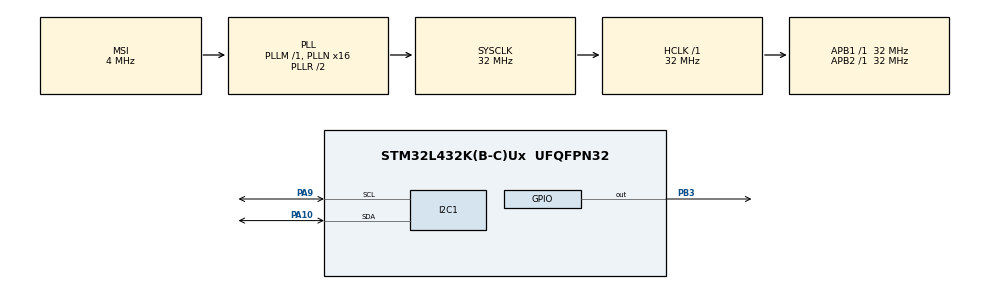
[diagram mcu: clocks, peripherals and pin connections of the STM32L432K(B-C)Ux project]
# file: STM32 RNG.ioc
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I2C1.OwnAddress=42
I2C1.Timing=0x00B07CB4
Mcu.Family=STM32L4
Mcu.Name=STM32L432K(B-C)Ux
Mcu.Package=UFQFPN32
NUCLEO-L432KC.LD3=true
NVIC.I2C1_ER_IRQn=true\:0\:0\:false\:false\:true\:true\:true\:true
NVIC.I2C1_EV_IRQn=true\:0\:0\:false\:false\:true\:true\:true\:true
NVIC.PriorityGroup=NVIC_PRIORITYGROUP_4
PA0.GPIO_Label=MCO [High speed clock in]
PA0.Signal=RCC_CK_IN
PA10.GPIO_Pu=GPIO_PULLUP
PA10.Mode=I2C
PA10.Signal=I2C1_SDA
PA13\ (JTMS-SWDIO).GPIO_Label=SWDIO
PA13\ (JTMS-SWDIO).Signal=SYS_JTMS-SWDIO
PA14\ (JTCK-SWCLK).GPIO_Label=SWCLK
PA14\ (JTCK-SWCLK).Signal=SYS_JTCK-SWCLK
PA15\ (JTDI).GPIO_Label=VCP_RX
PA15\ (JTDI).Signal=USART2_RX
PA2.GPIO_Label=VCP_TX
PA2.Signal=USART2_TX
PA9.GPIO_Pu=GPIO_PULLUP
PA9.Mode=I2C
PA9.Signal=I2C1_SCL
PB3\ (JTDO-TRACESWO).Signal=GPIO_Output
PC14-OSC32_IN\ (PC14).Signal=RCC_OSC32_IN
PC15-OSC32_OUT\ (PC15).Signal=RCC_OSC32_OUT
ProjectManager.HeapSize=0x200
ProjectManager.StackSize=0x400
ProjectManager.TargetToolchain=STM32CubeIDE
RCC.AHBFreq_Value=32000000
RCC.APB1Freq_Value=32000000
RCC.APB1TimFreq_Value=32000000
RCC.APB2Freq_Value=32000000
RCC.APB2TimFreq_Value=32000000
RCC.CortexFreq_Value=32000000
RCC.HCLKFreq_Value=32000000
RCC.HSE_VALUE=8000000
RCC.HSI16_VALUE=16000000
RCC.HSI48_VALUE=48000000
RCC.HSI_VALUE=16000000
RCC.LSE_VALUE=32768
RCC.MSI_VALUE=4000000
RCC.PLLMUL=RCC_PLLMUL_4
RCC.PLLN=16
RCC.SYSCLKFreq_VALUE=32000000
RCC.SYSCLKSource=RCC_SYSCLKSOURCE_PLLCLK
RCC.VCOOutputFreq_Value=64000000
VP_NUCLEO-L432KC_VS_BSP_COMMON.Mode=COMMON
board=NUCLEO-L432KC

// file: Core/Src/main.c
/* USER CODE BEGIN Header */
/**
  ******************************************************************************
  * @file           : main.c
  * @brief          : Main program body
  ******************************************************************************
  * @attention
  *
  * Copyright (c) 2026 STMicroelectronics.
  * All rights reserved.
  *
  * This software is licensed under terms that can be found in the LICENSE file
  * in the root directory of this software component.
  * If no LICENSE file comes with this software, it is provided AS-IS.
  *
  ******************************************************************************
  */
/* USER CODE END Header */
#include "main.h"

/* USER CODE BEGIN Includes */
#include <stdio.h>
#include <stdlib.h>
#include <time.h>
/* USER CODE END Includes */

I2C_HandleTypeDef hi2c1;

/* USER CODE BEGIN PV */
volatile uint8_t restart = 1;
/* USER CODE END PV */

void SystemClock_Config(void);
static void MX_GPIO_Init(void);
static void MX_I2C1_Init(void);
/* USER CODE BEGIN PFP */
void HAL_I2C_SlaveTxCpltCallback(I2C_HandleTypeDef *hi2c)
{
	restart = 1;

}
/* USER CODE END PFP */

int main(void)
{

  /* MCU Configuration--------------------------------------------------------*/

  /* Reset of all peripherals, Initializes the Flash interface and the Systick. */
  HAL_Init();

  /* Configure the system clock */
  SystemClock_Config();

  /* Initialize all configured peripherals */
  MX_GPIO_Init();
  MX_I2C1_Init();

  /* Initialize leds */
  BSP_LED_Init(LED_GREEN);

  /* Infinite loop */
  /* USER CODE BEGIN WHILE */

  uint8_t payload[3], test = {0};
  srand((unsigned int)time(NULL));
  while (1)
  {
	  payload[0] = (rand() % 5) + 1;
	  payload[1] = (rand() % 5) + 1;
	  payload[2] = (rand() % 10) + 1;
    /* USER CODE END WHILE */

    /* USER CODE BEGIN 3 */
	  if (restart)
	          {
	              restart = 0;

	              // regenerate all RNG numbers
	              payload[0] = (uint8_t)((rand() % 5) + 1);
	              payload[1] = (uint8_t)((rand() % 5) + 1);
	              payload[2] = (uint8_t)((rand() % 10) + 1);

	              // re-arm the listener
	              HAL_I2C_Slave_Transmit_IT(&hi2c1, payload, 3);
	          }
  }
  /* USER CODE END 3 */
}

void SystemClock_Config(void)
{
  RCC_OscInitTypeDef RCC_OscInitStruct = {0};
  RCC_ClkInitTypeDef RCC_ClkInitStruct = {0};

  /** Configure the main internal regulator output voltage
  */
  if (HAL_PWREx_ControlVoltageScaling(PWR_REGULATOR_VOLTAGE_SCALE1) != HAL_OK)
  {
    Error_Handler();
  }

  /** Initializes the RCC Oscillators according to the specified parameters
  * in the RCC_OscInitTypeDef structure.
  */
  RCC_OscInitStruct.OscillatorType = RCC_OSCILLATORTYPE_MSI;
  RCC_OscInitStruct.MSIState = RCC_MSI_ON;
  RCC_OscInitStruct.MSICalibrationValue = 0;
  RCC_OscInitStruct.MSIClockRange = RCC_MSIRANGE_6;
  RCC_OscInitStruct.PLL.PLLState = RCC_PLL_ON;
  RCC_OscInitStruct.PLL.PLLSource = RCC_PLLSOURCE_MSI;
  RCC_OscInitStruct.PLL.PLLM = 1;
  RCC_OscInitStruct.PLL.PLLN = 16;
  RCC_OscInitStruct.PLL.PLLP = RCC_PLLP_DIV7;
  RCC_OscInitStruct.PLL.PLLQ = RCC_PLLQ_DIV2;
  RCC_OscInitStruct.PLL.PLLR = RCC_PLLR_DIV2;
  if (HAL_RCC_OscConfig(&RCC_OscInitStruct) != HAL_OK)
  {
    Error_Handler();
  }

  /** Initializes the CPU, AHB and APB buses clocks
  */
  RCC_ClkInitStruct.ClockType = RCC_CLOCKTYPE_HCLK|RCC_CLOCKTYPE_SYSCLK
                              |RCC_CLOCKTYPE_PCLK1|RCC_CLOCKTYPE_PCLK2;
  RCC_ClkInitStruct.SYSCLKSource = RCC_SYSCLKSOURCE_PLLCLK;
  RCC_ClkInitStruct.AHBCLKDivider = RCC_SYSCLK_DIV1;
  RCC_ClkInitStruct.APB1CLKDivider = RCC_HCLK_DIV1;
  RCC_ClkInitStruct.APB2CLKDivider = RCC_HCLK_DIV1;

  if (HAL_RCC_ClockConfig(&RCC_ClkInitStruct, FLASH_LATENCY_1) != HAL_OK)
  {
    Error_Handler();
  }
}

static void MX_I2C1_Init(void)
{

  hi2c1.Instance = I2C1;
  hi2c1.Init.Timing = 0x00B07CB4;
  hi2c1.Init.OwnAddress1 = 84;
  hi2c1.Init.AddressingMode = I2C_ADDRESSINGMODE_7BIT;
  hi2c1.Init.DualAddressMode = I2C_DUALADDRESS_DISABLE;
  hi2c1.Init.OwnAddress2 = 0;
  hi2c1.Init.OwnAddress2Masks = I2C_OA2_NOMASK;
  hi2c1.Init.GeneralCallMode = I2C_GENERALCALL_DISABLE;
  hi2c1.Init.NoStretchMode = I2C_NOSTRETCH_DISABLE;
  if (HAL_I2C_Init(&hi2c1) != HAL_OK)
  {
    Error_Handler();
  }

  /** Configure Analogue filter
  */
  if (HAL_I2CEx_ConfigAnalogFilter(&hi2c1, I2C_ANALOGFILTER_ENABLE) != HAL_OK)
  {
    Error_Handler();
  }

  /** Configure Digital filter
  */
  if (HAL_I2CEx_ConfigDigitalFilter(&hi2c1, 0) != HAL_OK)
  {
    Error_Handler();
  }

}

static void MX_GPIO_Init(void)
{
  GPIO_InitTypeDef GPIO_InitStruct = {0};

  /* GPIO Ports Clock Enable */
  __HAL_RCC_GPIOC_CLK_ENABLE();
  __HAL_RCC_GPIOA_CLK_ENABLE();

  /*Configure GPIO pin : VCP_TX_Pin */
  GPIO_InitStruct.Pin = VCP_TX_Pin;
  GPIO_InitStruct.Mode = GPIO_MODE_AF_PP;
  GPIO_InitStruct.Pull = GPIO_NOPULL;
  GPIO_InitStruct.Speed = GPIO_SPEED_FREQ_VERY_HIGH;
  GPIO_InitStruct.Alternate = GPIO_AF7_USART2;
  HAL_GPIO_Init(VCP_TX_GPIO_Port, &GPIO_InitStruct);

  /*Configure GPIO pin : VCP_RX_Pin */
  GPIO_InitStruct.Pin = VCP_RX_Pin;
  GPIO_InitStruct.Mode = GPIO_MODE_AF_PP;
  GPIO_InitStruct.Pull = GPIO_NOPULL;
  GPIO_InitStruct.Speed = GPIO_SPEED_FREQ_VERY_HIGH;
  GPIO_InitStruct.Alternate = GPIO_AF3_USART2;
  HAL_GPIO_Init(VCP_RX_GPIO_Port, &GPIO_InitStruct);

}

void Error_Handler(void)
{
  __disable_irq();
  while (1)
  {
  }
}
